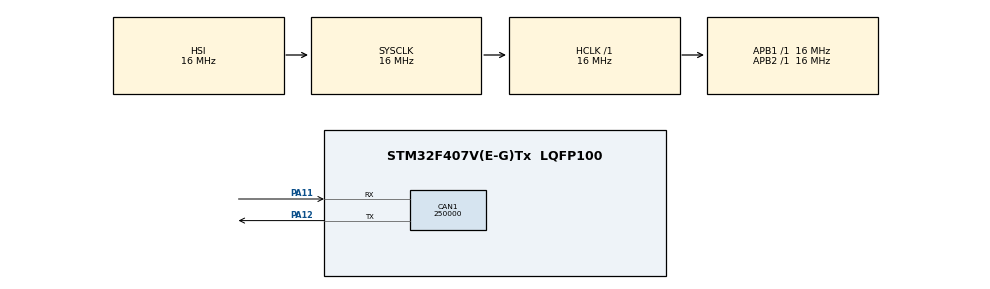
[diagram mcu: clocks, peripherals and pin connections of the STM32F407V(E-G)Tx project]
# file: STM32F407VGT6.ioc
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CAN1.BS2=CAN_BS2_2TQ
CAN1.CalculateBaudRate=250000
CAN1.CalculateTimeBit=4000.00
CAN1.CalculateTimeQuantum=1000.0
CAN1.Mode=CAN_MODE_LOOPBACK
Mcu.Family=STM32F4
Mcu.Name=STM32F407V(E-G)Tx
Mcu.Package=LQFP100
NVIC.CAN1_RX0_IRQn=true\:0\:0\:false\:false\:true\:true\:true
NVIC.CAN1_TX_IRQn=true\:0\:0\:false\:false\:true\:true\:true
NVIC.PriorityGroup=NVIC_PRIORITYGROUP_4
PA11.Mode=CAN_Activate
PA11.Signal=CAN1_RX
PA12.Mode=CAN_Activate
PA12.Signal=CAN1_TX
ProjectManager.HeapSize=0x200
ProjectManager.StackSize=0x400
ProjectManager.TargetToolchain=STM32CubeIDE
RCC.AHBFreq_Value=16000000
RCC.APB1Freq_Value=16000000
RCC.APB2Freq_Value=16000000
RCC.CortexFreq_Value=16000000
RCC.HSE_VALUE=25000000
RCC.HSI_VALUE=16000000
RCC.LSE_VALUE=32768
RCC.SYSCLKFreq_VALUE=16000000
RCC.VCOOutputFreq_Value=192000000
board=custom

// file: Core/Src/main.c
/* USER CODE BEGIN Header */
/**
  ******************************************************************************
  * @file           : main.c
  * @brief          : Main program body
  ******************************************************************************
  * @attention
  *
  * <h2><center>&copy; Copyright (c) 2021 STMicroelectronics.
  * All rights reserved.</center></h2>
  *
  * This software component is licensed by ST under BSD 3-Clause license,
  * the "License"; You may not use this file except in compliance with the
  * License. You may obtain a copy of the License at:
  *                        opensource.org/licenses/BSD-3-Clause
  *
  ******************************************************************************
  */
/* USER CODE END Header */
#include "main.h"

CAN_HandleTypeDef hcan1;

/* USER CODE BEGIN PV */
CAN_FilterTypeDef sFilterConfig;
CAN_TxHeaderTypeDef TxHeader;
CAN_RxHeaderTypeDef RxHeader;
/* USER CODE END PV */

void SystemClock_Config(void);
static void MX_GPIO_Init(void);
static void MX_CAN1_Init(void);

int main(void)
{

  /* MCU Configuration--------------------------------------------------------*/

  /* Reset of all peripherals, Initializes the Flash interface and the Systick. */
  HAL_Init();

  /* Configure the system clock */
  SystemClock_Config();

  /* Initialize all configured peripherals */
  MX_GPIO_Init();
  MX_CAN1_Init();
  /* USER CODE BEGIN 2 */
  sFilterConfig.FilterBank = 0;
  sFilterConfig.FilterMode = CAN_FILTERMODE_IDMASK;
  sFilterConfig.FilterScale = CAN_FILTERSCALE_32BIT;
  sFilterConfig.FilterIdHigh = 0x033<<5;
  sFilterConfig.FilterIdLow = 0x0000;
  sFilterConfig.FilterMaskIdHigh = 0x0000;
  sFilterConfig.FilterMaskIdLow = 0x0000;
  sFilterConfig.FilterFIFOAssignment = CAN_RX_FIFO0;
  sFilterConfig.FilterActivation = ENABLE;
  sFilterConfig.SlaveStartFilterBank = 14;

  if (HAL_CAN_ConfigFilter(&hcan1, &sFilterConfig) != HAL_OK)
  	  {
  	  Error_Handler();
    }

    if (HAL_CAN_Start(&hcan1) != HAL_OK)
    {
  	  /* Start Error */
  	  Error_Handler();
    }

    if (HAL_CAN_ActivateNotification(&hcan1, CAN_IT_RX_FIFO0_OVERRUN) != HAL_OK)
    {

  	  Error_Handler();
    }
    if (HAL_CAN_ActivateNotification(&hcan1, CAN_IT_TX_MAILBOX_EMPTY) != HAL_OK)
    {

  	  Error_Handler();
    }

    TxHeader.StdId = 0x07; //07
    //TxHeader.ExtId = 0x01; //delete
    TxHeader.RTR = CAN_RTR_DATA;
    TxHeader.IDE = CAN_ID_STD;
    TxHeader.DLC = 8;
    TxHeader.TransmitGlobalTime = DISABLE;
  /* USER CODE END 2 */

  /* Infinite loop */
  /* USER CODE BEGIN WHILE */
  uint8_t data[] = {8};
  uint32_t TxMailboxes;
  uint32_t RxFifo = 1;
  uint8_t rxdata[1];

  while (1)
  {
    /* USER CODE END WHILE */
	  while(HAL_CAN_AddTxMessage(&hcan1, &TxHeader, data, &TxMailboxes)!=HAL_OK);
	  while(HAL_CAN_IsTxMessagePending(&hcan1,TxMailboxes)!=0);
	  while(HAL_CAN_GetRxMessage(&hcan1, RxFifo, &RxHeader, rxdata)!=HAL_OK);
	  printf(rxdata[0]);

  }
}

void SystemClock_Config(void)
{
  RCC_OscInitTypeDef RCC_OscInitStruct = {0};
  RCC_ClkInitTypeDef RCC_ClkInitStruct = {0};

  /** Configure the main internal regulator output voltage
  */
  __HAL_RCC_PWR_CLK_ENABLE();
  __HAL_PWR_VOLTAGESCALING_CONFIG(PWR_REGULATOR_VOLTAGE_SCALE1);
  /** Initializes the RCC Oscillators according to the specified parameters
  * in the RCC_OscInitTypeDef structure.
  */
  RCC_OscInitStruct.OscillatorType = RCC_OSCILLATORTYPE_HSI;
  RCC_OscInitStruct.HSIState = RCC_HSI_ON;
  RCC_OscInitStruct.HSICalibrationValue = RCC_HSICALIBRATION_DEFAULT;
  RCC_OscInitStruct.PLL.PLLState = RCC_PLL_NONE;
  if (HAL_RCC_OscConfig(&RCC_OscInitStruct) != HAL_OK)
  {
    Error_Handler();
  }
  /** Initializes the CPU, AHB and APB buses clocks
  */
  RCC_ClkInitStruct.ClockType = RCC_CLOCKTYPE_HCLK|RCC_CLOCKTYPE_SYSCLK
                              |RCC_CLOCKTYPE_PCLK1|RCC_CLOCKTYPE_PCLK2;
  RCC_ClkInitStruct.SYSCLKSource = RCC_SYSCLKSOURCE_HSI;
  RCC_ClkInitStruct.AHBCLKDivider = RCC_SYSCLK_DIV1;
  RCC_ClkInitStruct.APB1CLKDivider = RCC_HCLK_DIV1;
  RCC_ClkInitStruct.APB2CLKDivider = RCC_HCLK_DIV1;

  if (HAL_RCC_ClockConfig(&RCC_ClkInitStruct, FLASH_LATENCY_0) != HAL_OK)
  {
    Error_Handler();
  }
}

static void MX_CAN1_Init(void)
{

  hcan1.Instance = CAN1;
  hcan1.Init.Prescaler = 16;
  hcan1.Init.Mode = CAN_MODE_LOOPBACK;
  hcan1.Init.SyncJumpWidth = CAN_SJW_1TQ;
  hcan1.Init.TimeSeg1 = CAN_BS1_1TQ;
  hcan1.Init.TimeSeg2 = CAN_BS2_2TQ;
  hcan1.Init.TimeTriggeredMode = DISABLE;
  hcan1.Init.AutoBusOff = DISABLE;
  hcan1.Init.AutoWakeUp = DISABLE;
  hcan1.Init.AutoRetransmission = DISABLE;
  hcan1.Init.ReceiveFifoLocked = DISABLE;
  hcan1.Init.TransmitFifoPriority = DISABLE;
  if (HAL_CAN_Init(&hcan1) != HAL_OK)
  {
    Error_Handler();
  }

}

static void MX_GPIO_Init(void)
{

  /* GPIO Ports Clock Enable */
  __HAL_RCC_GPIOA_CLK_ENABLE();

}

void Error_Handler(void)
{
  __disable_irq();
  while (1)
  {
  }
}

/************************ (C) COPYRIGHT STMicroelectronics *****END OF FILE****/
